# nRF54h20_secure register map
Vendor: Nordic Semiconductor; Series: nRF54h; File version: 1
CPU: CM33 r0p4, little endian, MPU, no FPU, 3 interrupt priority bits, 480 interrupts, 8 SAU regions
Registers are 32-bit, read-write, reset 0x0 unless marked. A register's access mark holds for its fields unless they carry their own. Offsets are from the block's base; [hi:lo] are bit positions; lines under a group give offsets from that group; {n}, {i} and the like mark numbered series; 'fields as' and 'values as' point back to an identical list.

## GLOBAL_STMDATA_NS — System Trace Macrocell data buffer 0
Base 0xA0000000
Same registers: GLOBAL_STMDATA_S 0xA0000000 (alternate view of GLOBAL_STMDATA_NS)
{0x0+0x1000000*i} DOMAIN[{i}] (i=0..15) group — Unspecified
  {0x0+j} DATA[{j}] (j=0..16777215) 8-bit — Description collection: STM extended stimulus port data buffer area for domain n. NonSecure writes to this region generates trace packets with id n+96. Secure writes to this region generates trace packets with id n+32.

## GLOBAL_TDDCONF_NS — TDDCONF 0
Base 0xBF001000
Same registers: GLOBAL_TDDCONF_S 0xBF001000 (alternate view of GLOBAL_TDDCONF_NS)
0x400 SYSPWRUPREQ — System power-up request
  [0] ACTIVE — Activate power-up request
    0=NotActive (Power-up request not active); 1=Active (Power-up request active)
0x404 DBGPWRUPREQ — Debug power-up request
  fields as SYSPWRUPREQ
0x408 TRACEPORTSPEED — Trace port trace clock speed
  [1:0] SPEED — Trace clock speed
    0=Speed80MHz; 1=Speed40MHz; 2=Speed20MHz; 3=Speed10MHz
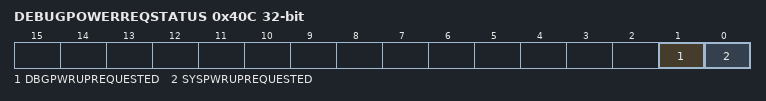
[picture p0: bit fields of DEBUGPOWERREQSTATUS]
0x40C DEBUGPOWERREQSTATUS ro — Combined effective system status of both SWJ-DP and TDDCONF registers originated power requests
  [1] DBGPWRUPREQUESTED — Debug domain powerup request status
    0=NoPowerReq (Power not requested); 1=Power requested
  [0] SYSPWRUPREQUESTED — System powerup request status
    0=NoPowerReq (Power not requested); 1=Power requested

## BELLBOARD_NS — BELLBOARD APB registers 0
Base 0x4F099000
Same registers: BELLBOARD_S 0x5F099000
{0x0+4i} TASKS_TRIGGER[{i}] (i=0..31) wo — Description collection: Task TRIGGER[n]
  [0] TASKS_TRIGGER — Task TRIGGER[n]
    1=Trigger task
{0x100+4i} EVENTS_TRIGGERED[{i}] (i=0..31) — Description collection: Event TRIGGERED[n]
  [0] EVENTS_TRIGGERED — Event TRIGGERED[n]
    0=NotGenerated (Event not generated); 1=Generated (Event generated)
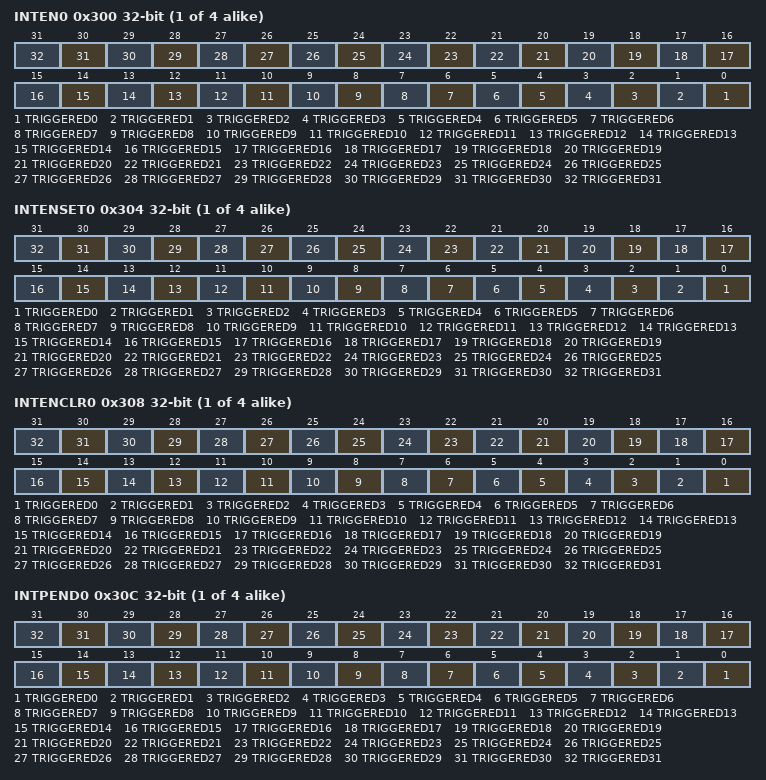
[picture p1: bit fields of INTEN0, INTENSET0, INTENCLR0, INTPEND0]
{0x300+0x10*i} INTEN{i} (i=0..3) — Enable or disable interrupt
  [all] fields
    0=Disabled; 1=Enabled
  [n] TRIGGERED{n} (n=0..31) — Enable or disable interrupt for event TRIGGERED[{n}]
{0x304+0x10*i} INTENSET{i} (i=0..3) — Enable interrupt
  [all] fields
    on read: 0=Disabled (Read: Disabled); 1=Enabled (Read: Enabled) | on write: 1=Set (Enable)
  [n] TRIGGERED{n} (n=0..31) — Write '1' to enable interrupt for event TRIGGERED[{n}]
{0x308+0x10*i} INTENCLR{i} (i=0..3) — Disable interrupt
  [all] fields
    on read: 0=Disabled (Read: Disabled); 1=Enabled (Read: Enabled) | on write: 1=Clear (Disable)
  [n] TRIGGERED{n} (n=0..31) — Write '1' to disable interrupt for event TRIGGERED[{n}]
{0x30C+0x10*i} INTPEND{i} ro (i=0..3) — Pending interrupts
  [all] fields
    on read: 0=NotPending (Read: Not pending); 1=Pending (Read: Pending)
  [n] TRIGGERED{n} (n=0..31) — Read pending status of interrupt for event TRIGGERED[{n}]

## GLOBAL_TBM_NS — Trace buffer monitor 0
Base 0xBF003000
Same registers: GLOBAL_TBM_S 0xBF003000 (alternate view of GLOBAL_TBM_NS)
0x00 TASKS_START wo — Start counter
  [0] TASKS_START
    1=Trigger task
0x04 TASKS_STOP wo — Stop counter, clear counter value
  [0] TASKS_STOP
    1=Trigger task
0x08 TASKS_FLUSH wo — Save current counter value to COUNTSNAPSHOT
  [0] TASKS_FLUSH
    1=Trigger task
0x100 EVENTS_HALFFULL — Counter value equals half-full
  [0] EVENTS_HALFFULL
    0=NotGenerated (Event not generated); 1=Generated (Event generated)
0x104 EVENTS_FULL — Counter value equals full
  [0] EVENTS_FULL
    values as EVENTS_HALFFULL.EVENTS_HALFFULL
0x108 EVENTS_FLUSH — Counter value saved to COUNTSNAPSHOT due to flush
  [0] EVENTS_FLUSH
    values as EVENTS_HALFFULL.EVENTS_HALFFULL
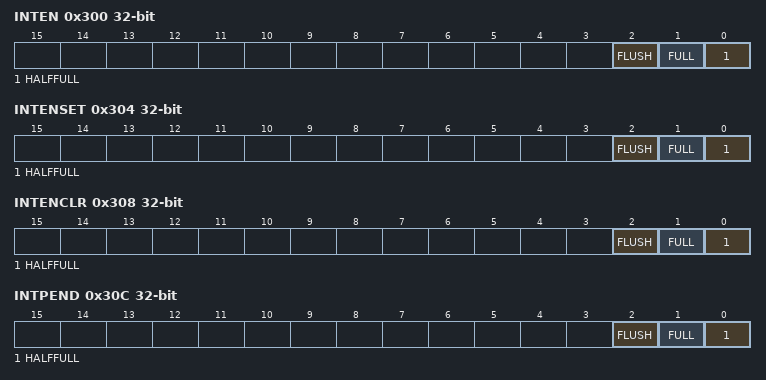
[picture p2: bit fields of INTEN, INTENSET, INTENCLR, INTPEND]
0x300 INTEN — Enable or disable interrupt
  [all] fields
    0=Disabled; 1=Enabled
  [2] FLUSH — Enable or disable interrupt for event FLUSH
  [1] FULL — Enable or disable interrupt for event FULL
  [0] HALFFULL — Enable or disable interrupt for event HALFFULL
0x304 INTENSET — Enable interrupt
  [all] fields
    on read: 0=Disabled (Read: Disabled); 1=Enabled (Read: Enabled) | on write: 1=Set (Enable)
  [2] FLUSH — Write '1' to enable interrupt for event FLUSH
  [1] FULL — Write '1' to enable interrupt for event FULL
  [0] HALFFULL — Write '1' to enable interrupt for event HALFFULL
0x308 INTENCLR — Disable interrupt
  [all] fields
    on read: 0=Disabled (Read: Disabled); 1=Enabled (Read: Enabled) | on write: 1=Clear (Disable)
  [2] FLUSH — Write '1' to disable interrupt for event FLUSH
  [1] FULL — Write '1' to disable interrupt for event FULL
  [0] HALFFULL — Write '1' to disable interrupt for event HALFFULL
0x30C INTPEND ro — Pending interrupts
  [all] fields
    on read: 0=NotPending (Read: Not pending); 1=Pending (Read: Pending)
  [2] FLUSH — Read pending status of interrupt for event FLUSH
  [1] FULL — Read pending status of interrupt for event FULL
  [0] HALFFULL — Read pending status of interrupt for event HALFFULL
0x400 BUFFERSIZE reset 0x400 — System RAM trace buffer total size in bytes
  [12:0] BUFFERSIZE — Must only be configured in STOP mode. Must be programmed to multiple of 16 bytes to make half-buffer size always 64 bit word aligned. Typical minimum BUFFERSIZE value 0x010 i.e. 16 bytes, typical maximum value 0x1000 i.e. 4096 bytes.
    0=Zero (0 bytes); 16=Min (16 bytes); 0x1000=Max (4096 bytes)
0x404 COUNT — Counter current value
  [12:0] COUNT — Counter current value. Only writable when counter is in stopped state. Writing when not in stopped state will generate a bus fault.
0x408 COUNTSNAPSHOT ro — Copy of the current COUNT value
  [12:0] COUNTSNAPSHOT — TASKS_FLUSH will copy the current COUNT value to this register.

## Notices in the file
Copyright (c) 2010 - 2025, Nordic Semiconductor ASA All rights reserved.
SPDX-License-Identifier: BSD-3-Clause
Redistribution and use in source and binary forms, with or without
modification, are permitted provided that the following conditions are met:
1. Redistributions of source code must retain the above copyright notice, this
list of conditions and the following disclaimer.
2. Redistributions in binary form must reproduce the above copyright
notice, this list of conditions and the following disclaimer in the
documentation and/or other materials provided with the distribution.
3. Neither the name of Nordic Semiconductor ASA nor the names of its
contributors may be used to endorse or promote products derived from this
software without specific prior written permission.
THIS SOFTWARE IS PROVIDED BY THE COPYRIGHT HOLDERS AND CONTRIBUTORS "AS IS"
AND ANY EXPRESS OR IMPLIED WARRANTIES, INCLUDING, BUT NOT LIMITED TO, THE
IMPLIED WARRANTIES OF MERCHANTABILITY, AND FITNESS FOR A PARTICULAR PURPOSE
ARE DISCLAIMED. IN NO EVENT SHALL NORDIC SEMICONDUCTOR ASA OR CONTRIBUTORS BE
LIABLE FOR ANY DIRECT, INDIRECT, INCIDENTAL, SPECIAL, EXEMPLARY, OR
CONSEQUENTIAL DAMAGES (INCLUDING, BUT NOT LIMITED TO, PROCUREMENT OF
SUBSTITUTE GOODS OR SERVICES; LOSS OF USE, DATA, OR PROFITS; OR BUSINESS
INTERRUPTION) HOWEVER CAUSED AND ON ANY THEORY OF LIABILITY, WHETHER IN
CONTRACT, STRICT LIABILITY, OR TORT (INCLUDING NEGLIGENCE OR OTHERWISE)
ARISING IN ANY WAY OUT OF THE USE OF THIS SOFTWARE, EVEN IF ADVISED OF THE
POSSIBILITY OF SUCH DAMAGE.
